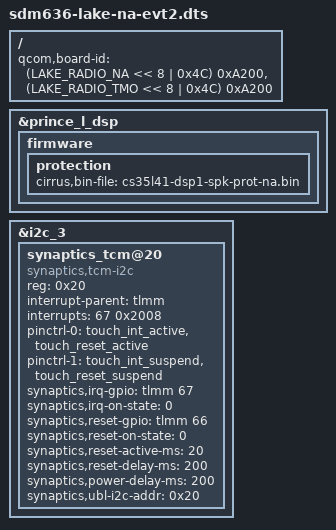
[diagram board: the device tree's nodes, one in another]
/* Copyright (c) 2018, Motorola Mobility Inc. All rights reserved.
 *
 * This program is free software; you can redistribute it and/or modify
 * it under the terms of the GNU General Public License version 2 and
 * only version 2 as published by the Free Software Foundation.
 *
 * This program is distributed in the hope that it will be useful,
 * but WITHOUT ANY WARRANTY; without even the implied warranty of
 * MERCHANTABILITY or FITNESS FOR A PARTICULAR PURPOSE.  See the
 * GNU General Public License for more details.
 */


/dts-v1/;

#include "sdm636.dtsi"
#include "sdm636-lake.dtsi"

/ {
	qcom,board-id = <(LAKE_RADIO_NA << 8 | 0x4C) 0xA200>,<(LAKE_RADIO_TMO << 8 | 0x4C) 0xA200>;
};

/*
 * Lake NA HW rev EVT1 specific changes go here
*/

&prince_l_dsp {
	firmware {
		protection {
			cirrus,bin-file = "cs35l41-dsp1-spk-prot-na.bin";
		};
	};
};

&i2c_3 {
	synaptics_tcm@20 {
		compatible = "synaptics,tcm-i2c";
		reg = <0x20>;
		interrupt-parent = <&tlmm>;
		interrupts = <67 0x2008>;
		pinctrl-names = "pmx_ts_active", "pmx_ts_suspend";
		pinctrl-0 = <&touch_int_active &touch_reset_active>;
		pinctrl-1 = <&touch_int_suspend &touch_reset_suspend>;
		synaptics,irq-gpio = <&tlmm 67 0x2008>; /* IRQF_ONESHOT | IRQF_TRIGGER_LOW */
		synaptics,irq-on-state = <0>;
		synaptics,reset-gpio = <&tlmm 66 0x0000>;
		synaptics,reset-on-state = <0>;
		synaptics,reset-active-ms = <20>;
		synaptics,reset-delay-ms = <200>;
		synaptics,power-delay-ms = <200>;
		synaptics,ubl-i2c-addr = <0x20>;
	};
};
